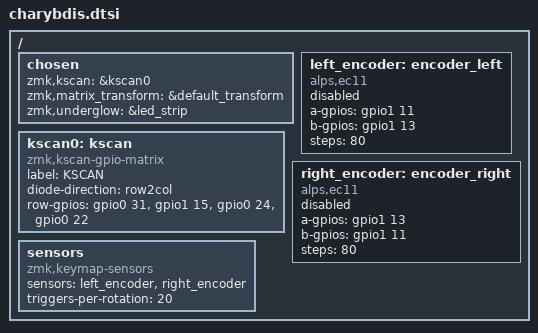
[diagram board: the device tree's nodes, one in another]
#include "charybdis-transform.dtsi"
#include <dt-bindings/led/led.h>

/ {
    chosen {
        zmk,kscan = &kscan0;
        zmk,matrix_transform = &default_transform;
	zmk,underglow = &led_strip;
    };

    kscan0: kscan {
        compatible = "zmk,kscan-gpio-matrix";
        label = "KSCAN";

        diode-direction = "row2col";
		row-gpios
            = <&gpio0 31 GPIO_ACTIVE_HIGH>
            , <&gpio1 15 GPIO_ACTIVE_HIGH>
            , <&gpio0 24 GPIO_ACTIVE_HIGH>
	        , <&gpio0 22 GPIO_ACTIVE_HIGH>
	      
            ;
    };
 left_encoder: encoder_left {
        compatible = "alps,ec11";
        a-gpios = <&gpio1 11 (GPIO_ACTIVE_HIGH | GPIO_PULL_UP)>;
        b-gpios = <&gpio1 13 (GPIO_ACTIVE_HIGH | GPIO_PULL_UP)>;
        steps = <80>;
        status = "disabled";
    };

    right_encoder: encoder_right {
        compatible = "alps,ec11";
      a-gpios = <&gpio1 13 (GPIO_ACTIVE_HIGH | GPIO_PULL_UP)>;
        b-gpios = <&gpio1 11 (GPIO_ACTIVE_HIGH | GPIO_PULL_UP)>;
        steps = <80>;
        status = "disabled";
    };

    sensors: sensors {
        compatible = "zmk,keymap-sensors";
        sensors = <&left_encoder &right_encoder>;
        triggers-per-rotation = <20>;
    };
};

